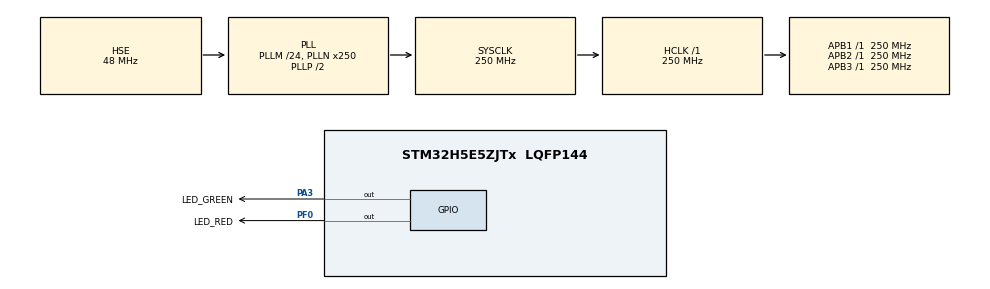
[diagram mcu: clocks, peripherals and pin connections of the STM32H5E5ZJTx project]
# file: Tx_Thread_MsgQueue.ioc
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CORTEX_M33_NS.userName=CORTEX_M33
Mcu.Family=STM32H5
Mcu.Name=STM32H5E5ZJTx
Mcu.Package=LQFP144
NVIC.PriorityGroup=NVIC_PRIORITYGROUP_4
NVIC.TIM6_IRQn=true\:15\:0\:false\:false\:true\:false\:false\:true\:true
NVIC.TimeBase=TIM6_IRQn
NVIC.TimeBaseIP=TIM6
PA3.GPIO_Label=LED_GREEN
PA3.GPIO_ModeDefaultOutputPP=GPIO_MODE_OUTPUT_PP
PA3.GPIO_PuPd=GPIO_NOPULL
PA3.GPIO_Speed=GPIO_SPEED_FREQ_VERY_HIGH
PA3.Signal=GPIO_Output
PF0.GPIO_Label=LED_RED
PF0.GPIO_Speed=GPIO_SPEED_FREQ_VERY_HIGH
PF0.Signal=GPIO_Output
PH0-OSC_IN(PH0).Mode=HSE-External-Oscillator
PH0-OSC_IN(PH0).Signal=RCC_OSC_IN
PH1-OSC_OUT(PH1).Mode=HSE-External-Oscillator
PH1-OSC_OUT(PH1).Signal=RCC_OSC_OUT
ProjectManager.HeapSize=0x200
ProjectManager.StackSize=0x400
ProjectManager.TargetToolchain=EWARM V9.20
RCC.ADCFreq_Value=250000000
RCC.AHBFreq_Value=250000000
RCC.APB1Freq_Value=250000000
RCC.APB1TimFreq_Value=250000000
RCC.APB2Freq_Value=250000000
RCC.APB2TimFreq_Value=250000000
RCC.APB3Freq_Value=250000000
RCC.CSI_VALUE=4000000
RCC.CortexFreq_Value=250000000
RCC.EPOD_VALUE=48000000
RCC.HCLKFreq_Value=250000000
RCC.HSE_VALUE=48000000
RCC.HSI48_VALUE=48000000
RCC.HSI_VALUE=64000000
RCC.LSE_VALUE=32768
RCC.LSIRC_VALUE=32000
RCC.PLLM=24
RCC.PLLN=250
RCC.PLLSourceVirtual=RCC_PLL1_SOURCE_HSE
RCC.SYSCLKFreq_VALUE=250000000
RCC.SYSCLKSource=RCC_SYSCLKSOURCE_PLLCLK
RCC.USBFreq_Value=258000000
RCC.VCOOutputFreq_Value=500000000
THREADX.TX_APP_CREATION=1
THREADX.TX_APP_GENERATE_INIT_CODE=true
THREADX.TX_APP_MEM_POOL_SIZE=3 * 1024
THREADX.TX_APP_MSG_QUEUE_CREATION=1
THREADX.TX_APP_THREAD_ENTRY=MsgSenderThreadOne_Entry
THREADX.TX_APP_THREAD_NAME=Message Queue Sender Thread One
THREADX.TX_APP_THREAD_PRIO=5
THREADX.TX_MSG_QUEUE_NAME=Message Queue One
THREADX.TX_NB_MSG=10
VP_CORTEX_M33_NS_VS_Hclk.Mode=Hclk_Mode
VP_ICACHE_VS_ICACHE.Mode=DefaultMode
VP_PWR_VS_LPOM.Mode=PowerOptimisation
VP_PWR_VS_SECSignals.Mode=Security/Privilege
VP_SYS_VS_tim6.Mode=TIM6
VP_THREADX_VS_RTOSJjThreadXJjCoreJjDefault.Mode=Core_Default
board=custom

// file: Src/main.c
/* USER CODE BEGIN Header */
/**
  ******************************************************************************
  * @file    ThreadX/Tx_Thread_MsgQueue/Src/main.c
  * @author  MCD Application Team
  * @brief   Main program body
  ******************************************************************************
  * @attention
  *
  * Copyright (c) 2026 STMicroelectronics.
  * All rights reserved.
  *
  * This software is licensed under terms that can be found in the LICENSE file
  * in the root directory of this software component.
  * If no LICENSE file comes with this software, it is provided AS-IS.
  *
  ******************************************************************************
  */
/* USER CODE END Header */
#include "app_threadx.h"
#include "main.h"

void SystemClock_Config(void);
static void MX_GPIO_Init(void);
static void MX_ICACHE_Init(void);

int main(void)
{

  /* MCU Configuration--------------------------------------------------------*/

  /* Reset of all peripherals, Initializes the Flash interface and the Systick. */
  HAL_Init();

  /* Configure the system clock */
  SystemClock_Config();

  /* Initialize all configured peripherals */
  MX_GPIO_Init();
  MX_ICACHE_Init();

  MX_ThreadX_Init();

  /* We should never get here as control is now taken by the scheduler */

  /* Infinite loop */
  while (1)
  {

  }
}

void SystemClock_Config(void)
{
  RCC_OscInitTypeDef RCC_OscInitStruct = {0};
  RCC_ClkInitTypeDef RCC_ClkInitStruct = {0};

  /** Configure the main internal regulator output voltage
  */
  __HAL_PWR_VOLTAGESCALING_CONFIG(PWR_REGULATOR_VOLTAGE_SCALE0);

  while(!__HAL_PWR_GET_FLAG(PWR_FLAG_VOSRDY)) {}

  /** Initializes the RCC Oscillators according to the specified parameters
  * in the RCC_OscInitTypeDef structure.
  */
  RCC_OscInitStruct.OscillatorType = RCC_OSCILLATORTYPE_HSE;
  RCC_OscInitStruct.HSEState = RCC_HSE_ON;
  RCC_OscInitStruct.PLL.PLLState = RCC_PLL_ON;
  RCC_OscInitStruct.PLL.PLLSource = RCC_PLL1_SOURCE_HSE;
  RCC_OscInitStruct.PLL.PLLM = 24;
  RCC_OscInitStruct.PLL.PLLN = 250;
  RCC_OscInitStruct.PLL.PLLP = 2;
  RCC_OscInitStruct.PLL.PLLQ = 2;
  RCC_OscInitStruct.PLL.PLLR = 2;
  RCC_OscInitStruct.PLL.PLLRGE = RCC_PLL1_VCIRANGE_1;
  RCC_OscInitStruct.PLL.PLLVCOSEL = RCC_PLL1_VCORANGE_WIDE;
  RCC_OscInitStruct.PLL.PLLFRACN = 0;
  if (HAL_RCC_OscConfig(&RCC_OscInitStruct) != HAL_OK)
  {
    Error_Handler();
  }

  /** Initializes the CPU, AHB and APB buses clocks
  */
  RCC_ClkInitStruct.ClockType = RCC_CLOCKTYPE_HCLK|RCC_CLOCKTYPE_SYSCLK
                              |RCC_CLOCKTYPE_PCLK1|RCC_CLOCKTYPE_PCLK2
                              |RCC_CLOCKTYPE_PCLK3;
  RCC_ClkInitStruct.SYSCLKSource = RCC_SYSCLKSOURCE_PLLCLK;
  RCC_ClkInitStruct.AHBCLKDivider = RCC_SYSCLK_DIV1;
  RCC_ClkInitStruct.APB1CLKDivider = RCC_HCLK_DIV1;
  RCC_ClkInitStruct.APB2CLKDivider = RCC_HCLK_DIV1;
  RCC_ClkInitStruct.APB3CLKDivider = RCC_HCLK_DIV1;

  if (HAL_RCC_ClockConfig(&RCC_ClkInitStruct, FLASH_LATENCY_5) != HAL_OK)
  {
    Error_Handler();
  }

  /** Configure the programming delay
  */
  __HAL_FLASH_SET_PROGRAM_DELAY(FLASH_PROGRAMMING_DELAY_2);
}

static void MX_ICACHE_Init(void)
{

  /** Enable instruction cache (default 2-ways set associative cache)
  */
  if (HAL_ICACHE_Enable() != HAL_OK)
  {
    Error_Handler();
  }

}

static void MX_GPIO_Init(void)
{
  GPIO_InitTypeDef GPIO_InitStruct = {0};

  /* GPIO Ports Clock Enable */
  __HAL_RCC_GPIOF_CLK_ENABLE();
  __HAL_RCC_GPIOH_CLK_ENABLE();
  __HAL_RCC_GPIOA_CLK_ENABLE();

  /*Configure GPIO pin Output Level */
  HAL_GPIO_WritePin(LED_RED_GPIO_Port, LED_RED_Pin, GPIO_PIN_RESET);

  /*Configure GPIO pin Output Level */
  HAL_GPIO_WritePin(LED_GREEN_GPIO_Port, LED_GREEN_Pin, GPIO_PIN_RESET);

  /*Configure GPIO pin : LED_RED_Pin */
  GPIO_InitStruct.Pin = LED_RED_Pin;
  GPIO_InitStruct.Mode = GPIO_MODE_OUTPUT_PP;
  GPIO_InitStruct.Pull = GPIO_NOPULL;
  GPIO_InitStruct.Speed = GPIO_SPEED_FREQ_VERY_HIGH;
  HAL_GPIO_Init(LED_RED_GPIO_Port, &GPIO_InitStruct);

  /*Configure GPIO pin : LED_GREEN_Pin */
  GPIO_InitStruct.Pin = LED_GREEN_Pin;
  GPIO_InitStruct.Mode = GPIO_MODE_OUTPUT_PP;
  GPIO_InitStruct.Pull = GPIO_NOPULL;
  GPIO_InitStruct.Speed = GPIO_SPEED_FREQ_VERY_HIGH;
  HAL_GPIO_Init(LED_GREEN_GPIO_Port, &GPIO_InitStruct);

}

void HAL_TIM_PeriodElapsedCallback(TIM_HandleTypeDef *htim)
{
  if (htim->Instance == TIM6)
  {
    HAL_IncTick();
  }
}

void Error_Handler(void)
{
  /* USER CODE BEGIN Error_Handler_Debug */
  /* User can add his own implementation to report the HAL error return state */
  HAL_GPIO_WritePin(LED_GREEN_GPIO_Port, LED_GREEN_Pin, GPIO_PIN_RESET);
  while (1)
  {
    HAL_GPIO_TogglePin(LED_RED_GPIO_Port, LED_RED_Pin);
    HAL_Delay(1000);
  }
  /* USER CODE END Error_Handler_Debug */
}
